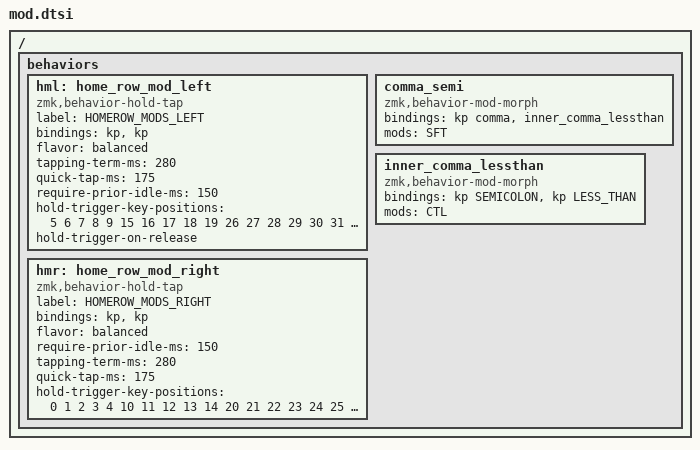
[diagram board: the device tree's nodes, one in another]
/ {
    behaviors {
        hml: home_row_mod_left {
            compatible = "zmk,behavior-hold-tap";
            label = "HOMEROW_MODS_LEFT";
            #binding-cells = <2>;
            bindings = <&kp>, <&kp>;

            flavor = "balanced";
            tapping-term-ms = <280>;
            quick-tap-ms = <175>;
            require-prior-idle-ms = <150>;
            hold-trigger-key-positions = <5 6 7 8 9 15 16 17 18 19 26 27 28 29 30 31 32 33 34 35 36 37>; 
            hold-trigger-on-release;
        };

        hmr: home_row_mod_right {
            compatible = "zmk,behavior-hold-tap";
            label = "HOMEROW_MODS_RIGHT";
            #binding-cells = <2>;
            bindings = <&kp>, <&kp>;

            flavor = "balanced";
            require-prior-idle-ms = <150>;
            tapping-term-ms = <280>;
            quick-tap-ms = <175>;
            hold-trigger-key-positions = <0 1 2 3 4 10 11 12 13 14 20 21 22 23 24 25 32 33 34 35 36 37>; 
        };


        // Tap: comma | Shift + tap: semicolon | Ctrl + shift + tap: <.
        comma_semi: comma_semi {
            compatible = "zmk,behavior-mod-morph";
            #binding-cells = <0>;

            bindings = <&kp comma>, <&inner_comma_lessthan>;
            mods = <SFT>;
        };

        inner_comma_lessthan: inner_comma_lessthan {
            compatible = "zmk,behavior-mod-morph";
            #binding-cells = <0>;
            
            bindings = <&kp SEMICOLON>, <&kp LESS_THAN>;
            mods = <CTL>;
        };
    };
};

